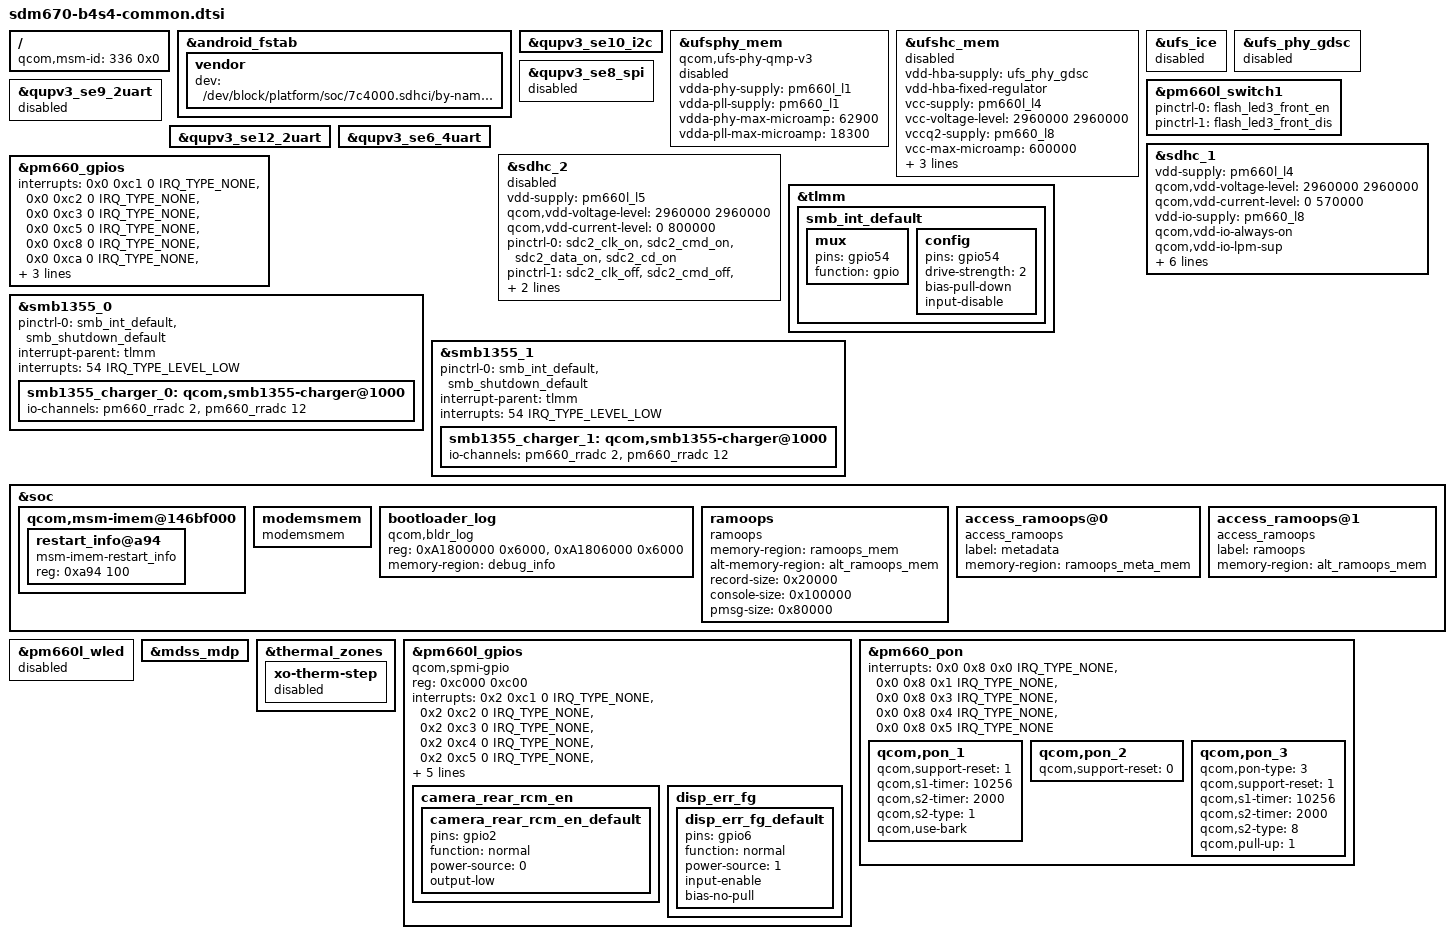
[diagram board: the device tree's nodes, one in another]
/* Copyright (c) 2017-2018, The Linux Foundation. All rights reserved.
 *
 * This program is free software; you can redistribute it and/or modify
 * it under the terms of the GNU General Public License version 2 and
 * only version 2 as published by the Free Software Foundation.
 *
 * This program is distributed in the hope that it will be useful,
 * but WITHOUT ANY WARRANTY; without even the implied warranty of
 * MERCHANTABILITY or FITNESS FOR A PARTICULAR PURPOSE.  See the
 * GNU General Public License for more details.
 */

/* Common BONITO, SARGO includes go here (i.e. not display) */
/* TODO: Split this file into bluetooth/keys/display/memory/power/thermal */

/plugin/;

#include <dt-bindings/clock/qcom,gcc-sdm845.h>
#include <dt-bindings/clock/qcom,camcc-sdm845.h>
#include <dt-bindings/clock/qcom,dispcc-sdm845.h>
#include <dt-bindings/clock/qcom,rpmh.h>
#include <dt-bindings/interrupt-controller/arm-gic.h>
#include <dt-bindings/regulator/qcom,rpmh-regulator.h>
#include <dt-bindings/clock/mdss-10nm-pll-clk.h>
#include <dt-bindings/gpio/gpio.h>

#include "../qcom/sdm670-pmic-overlay.dtsi"
#include "sdm670-b4s4-display.dtsi"
#include "sdm670-b4s4-pinctrl.dtsi"
#include "sdm670-b4s4-citadel.dtsi"
#include "sdm670-b4s4-audio.dtsi"
#include "sdm670-b4s4-memory.dtsi"
#include "sdm670-b4s4-fingerprint.dtsi"
#include "sdm670-b4s4-haptics.dtsi"
#include "sdm670-b4s4-key.dtsi"
#include "sdm670-b4s4-nfc.dtsi"
#include "sdm670-b4s4-usb-common.dtsi"
#include "sdm670-b4s4-thermal.dtsi"
#include "sdm670-b4s4-battery.dtsi"

/ {
	qcom,msm-id = <336 0x0>;
};

&android_fstab {
	vendor {
		dev = "/dev/block/platform/soc/7c4000.sdhci/by-name/vendor";
	};
};

&qupv3_se10_i2c {
#include "../qcom/smb1355.dtsi"
};

&ufsphy_mem {
	compatible = "qcom,ufs-phy-qmp-v3";

	vdda-phy-supply = <&pm660l_l1>; /* 0.88v */
	vdda-pll-supply = <&pm660_l1>; /* 1.2v */
	vdda-phy-max-microamp = <62900>;
	vdda-pll-max-microamp = <18300>;

	status = "disabled";
};

&ufshc_mem {
	vdd-hba-supply = <&ufs_phy_gdsc>;
	vdd-hba-fixed-regulator;
	vcc-supply = <&pm660l_l4>;
	vcc-voltage-level = <2960000 2960000>;
	vccq2-supply = <&pm660_l8>;
	vcc-max-microamp = <600000>;
	vccq2-max-microamp = <600000>;

	qcom,vddp-ref-clk-supply = <&pm660_l1>;
	qcom,vddp-ref-clk-max-microamp = <100>;

	status = "disabled";
};

&ufs_ice {
	status = "disabled";
};

&ufs_phy_gdsc {
	status = "disabled";
};

&pm660l_switch1 {
	pinctrl-names = "led_enable", "led_disable";
	pinctrl-0 = <&flash_led3_front_en>;
	pinctrl-1 = <&flash_led3_front_dis>;
};

&qupv3_se9_2uart {
	status = "disabled";
};

&qupv3_se12_2uart {
	status = "ok";
};

&qupv3_se8_spi {
	status = "disabled";
};

&qupv3_se10_i2c {
	status = "ok";
};

&qupv3_se6_4uart {
	status = "ok";
};

&sdhc_1 {
	vdd-supply = <&pm660l_l4>;
	qcom,vdd-voltage-level = <2960000 2960000>;
	qcom,vdd-current-level = <0 570000>;

	vdd-io-supply = <&pm660_l8>;
	qcom,vdd-io-always-on;
	qcom,vdd-io-lpm-sup;
	qcom,vdd-io-voltage-level = <1800000 1800000>;
	qcom,vdd-io-current-level = <0 325000>;

	pinctrl-names = "active", "sleep";
	pinctrl-0 = <&sdc1_clk_on  &sdc1_cmd_on &sdc1_data_on &sdc1_rclk_on>;
	pinctrl-1 = <&sdc1_clk_off &sdc1_cmd_off &sdc1_data_off &sdc1_rclk_off>;

	status = "ok";
};

&sdhc_2 {
	vdd-supply = <&pm660l_l5>;
	qcom,vdd-voltage-level = <2960000 2960000>;
	qcom,vdd-current-level = <0 800000>;

	pinctrl-names = "active", "sleep";
	pinctrl-0 = <&sdc2_clk_on &sdc2_cmd_on &sdc2_data_on &sdc2_cd_on>;
	pinctrl-1 = <&sdc2_clk_off &sdc2_cmd_off &sdc2_data_off &sdc2_cd_off>;

	cd-gpios = <&tlmm 96 0x1>;

	status = "disabled";
};

/* Remove pm660 gpio6 from disallowed list for ext_5v_boost. */
&pm660_gpios {
	interrupts = <0x0 0xc1 0 IRQ_TYPE_NONE>,
			<0x0 0xc2 0 IRQ_TYPE_NONE>,
			<0x0 0xc3 0 IRQ_TYPE_NONE>,
			<0x0 0xc5 0 IRQ_TYPE_NONE>,
			<0x0 0xc8 0 IRQ_TYPE_NONE>,
			<0x0 0xca 0 IRQ_TYPE_NONE>,
			<0x0 0xcb 0 IRQ_TYPE_NONE>,
			<0x0 0xcc 0 IRQ_TYPE_NONE>;
	interrupt-names = "pm660_gpio2", "pm660_gpio3",
			"pm660_gpio4", "pm660_gpio6",
			"pm660_gpio9", "pm660_gpio11",
			"pm660_gpio12", "pm660_gpio13";
	qcom,gpios-disallowed = <1 5 7 8 10>;
};

&tlmm {
	smb_int_default: smb_int_default {
		mux {
			pins = "gpio54";
			function = "gpio";
		};
		config {
			pins = "gpio54";
			drive-strength = <2>;
			bias-pull-down;
			input-disable;
		};
	};
};

&smb1355_0 {
	pinctrl-names = "default";
	pinctrl-0 = <&smb_int_default
			&smb_shutdown_default>;
	interrupt-parent = <&tlmm>;
	interrupts = <54 IRQ_TYPE_LEVEL_LOW>;
	smb1355_charger_0: qcom,smb1355-charger@1000 {
		io-channels = <&pm660_rradc 2>,
				<&pm660_rradc 12>;
		io-channel-names = "charger_temp",
				"charger_temp_max";
		status ="ok";
	};
};

&smb1355_1 {
	pinctrl-names = "default";
	pinctrl-0 = <&smb_int_default
			&smb_shutdown_default>;
	interrupt-parent = <&tlmm>;
	interrupts = <54 IRQ_TYPE_LEVEL_LOW>;
	smb1355_charger_1: qcom,smb1355-charger@1000 {
		io-channels = <&pm660_rradc 2>,
				<&pm660_rradc 12>;
		io-channel-names = "charger_temp",
				"charger_temp_max";
		status ="ok";
	};
};

&soc {
	qcom,msm-imem@146bf000 {
		restart_info@a94 {
			compatible = "msm-imem-restart_info";
			reg = <0xa94 100>;
		};
	};

	modemsmem {
		compatible = "modemsmem";
	};

	bootloader_log {
		compatible = "qcom,bldr_log";
		reg = <0xA1800000 0x6000>, <0xA1806000 0x6000>;
		reg-names = "bl_log", "bl_old_log";
		memory-region = <&debug_info>;
	};

	ramoops {
		compatible = "ramoops";
		memory-region = <&ramoops_mem>;
		alt-memory-region = <&alt_ramoops_mem>;
		record-size = <0x20000>;
		console-size = <0x100000>;
		pmsg-size = <0x80000>;
	};

	access_ramoops@0 {
		compatible = "access_ramoops";
		label = "metadata";
		memory-region = <&ramoops_meta_mem>;
	};

	access_ramoops@1 {
		compatible = "access_ramoops";
		label = "ramoops";
		memory-region = <&alt_ramoops_mem>;
	};
};

&pm660l_wled {
	status = "disabled";
};

&mdss_mdp {
	#cooling-cells = <2>;
};

&thermal_zones {
	xo-therm-step {
		status = "disabled";
	};
};

&pm660l_gpios {
	compatible = "qcom,spmi-gpio";
	reg = <0xc000 0xc00>;
	interrupts = <0x2 0xc1 0 IRQ_TYPE_NONE>,
			<0x2 0xc2 0 IRQ_TYPE_NONE>,
			<0x2 0xc3 0 IRQ_TYPE_NONE>,
			<0x2 0xc4 0 IRQ_TYPE_NONE>,
			<0x2 0xc5 0 IRQ_TYPE_NONE>,
			<0x2 0xc6 0 IRQ_TYPE_NONE>,
			<0x2 0xc7 0 IRQ_TYPE_NONE>,
			<0x2 0xc8 0 IRQ_TYPE_NONE>;
	interrupt-names = "pm660l_gpio2", "pm660l_gpio3",
			"pm660l_gpio4", "pm660l_gpio5",
			"pm660l_gpio6", "pm660l_gpio7",
			"pm660l_gpio8", "pm660l_gpio9";
	gpio-controller;
	#gpio-cells = <2>;
	qcom,gpios-disallowed = <1 10 11 12>;

	camera_rear_rcm_en {
		camera_rear_rcm_en_default: camera_rear_rcm_en_default {
			pins = "gpio2";
			function = "normal";
			power-source = <0>;
			output-low;
		};
	};

	disp_err_fg {
		disp_err_fg_default: disp_err_fg_default {
			pins = "gpio6";
			function = "normal";
			power-source = <1>;
			input-enable;
			bias-no-pull;
		};
	};
};

&pm660_pon {
	interrupts = 	<0x0 0x8 0x0 IRQ_TYPE_NONE>,
			<0x0 0x8 0x1 IRQ_TYPE_NONE>,
			<0x0 0x8 0x3 IRQ_TYPE_NONE>,
			<0x0 0x8 0x4 IRQ_TYPE_NONE>,
			<0x0 0x8 0x5 IRQ_TYPE_NONE>;
	interrupt-names = "kpdpwr", "resin", "kpdpwr-bark",
			"resin-bark", "kpdpwr-resin-bark";
	qcom,pon_1 {
		qcom,support-reset = <1>;
		qcom,s1-timer = <10256>;
		qcom,s2-timer = <2000>;
		qcom,s2-type = <1>;
		qcom,use-bark;
	};
	qcom,pon_2 {
		qcom,support-reset = <0>;
	};
	qcom,pon_3 {
		qcom,pon-type = <3>;
		qcom,support-reset = <1>;
		qcom,s1-timer = <10256>;
		qcom,s2-timer = <2000>;
		qcom,s2-type = <8>;
		qcom,pull-up = <1>;
	};
};
